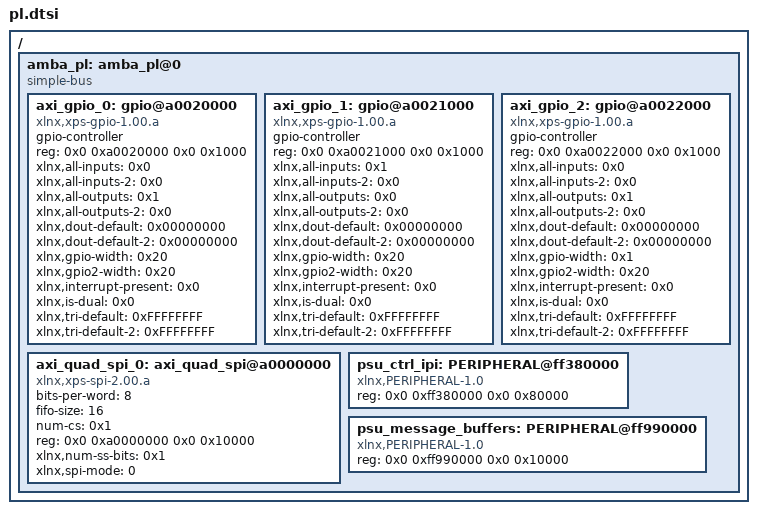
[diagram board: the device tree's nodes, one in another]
/*
 * CAUTION: This file is automatically generated by Xilinx.
 * Version:  
 * Today is: Mon Mar 15 13:33:53 2021
*/


/ {
	amba_pl: amba_pl@0 {
		#address-cells = <2>;
		#size-cells = <2>;
		compatible = "simple-bus";
		ranges ;
		axi_gpio_0: gpio@a0020000 {
			#gpio-cells = <2>;
			compatible = "xlnx,xps-gpio-1.00.a";
			gpio-controller ;
			reg = <0x0 0xa0020000 0x0 0x1000>;
			xlnx,all-inputs = <0x0>;
			xlnx,all-inputs-2 = <0x0>;
			xlnx,all-outputs = <0x1>;
			xlnx,all-outputs-2 = <0x0>;
			xlnx,dout-default = <0x00000000>;
			xlnx,dout-default-2 = <0x00000000>;
			xlnx,gpio-width = <0x20>;
			xlnx,gpio2-width = <0x20>;
			xlnx,interrupt-present = <0x0>;
			xlnx,is-dual = <0x0>;
			xlnx,tri-default = <0xFFFFFFFF>;
			xlnx,tri-default-2 = <0xFFFFFFFF>;
		};
		axi_gpio_1: gpio@a0021000 {
			#gpio-cells = <2>;
			compatible = "xlnx,xps-gpio-1.00.a";
			gpio-controller ;
			reg = <0x0 0xa0021000 0x0 0x1000>;
			xlnx,all-inputs = <0x1>;
			xlnx,all-inputs-2 = <0x0>;
			xlnx,all-outputs = <0x0>;
			xlnx,all-outputs-2 = <0x0>;
			xlnx,dout-default = <0x00000000>;
			xlnx,dout-default-2 = <0x00000000>;
			xlnx,gpio-width = <0x20>;
			xlnx,gpio2-width = <0x20>;
			xlnx,interrupt-present = <0x0>;
			xlnx,is-dual = <0x0>;
			xlnx,tri-default = <0xFFFFFFFF>;
			xlnx,tri-default-2 = <0xFFFFFFFF>;
		};
		axi_gpio_2: gpio@a0022000 {
			#gpio-cells = <2>;
			compatible = "xlnx,xps-gpio-1.00.a";
			gpio-controller ;
			reg = <0x0 0xa0022000 0x0 0x1000>;
			xlnx,all-inputs = <0x0>;
			xlnx,all-inputs-2 = <0x0>;
			xlnx,all-outputs = <0x1>;
			xlnx,all-outputs-2 = <0x0>;
			xlnx,dout-default = <0x00000000>;
			xlnx,dout-default-2 = <0x00000000>;
			xlnx,gpio-width = <0x1>;
			xlnx,gpio2-width = <0x20>;
			xlnx,interrupt-present = <0x0>;
			xlnx,is-dual = <0x0>;
			xlnx,tri-default = <0xFFFFFFFF>;
			xlnx,tri-default-2 = <0xFFFFFFFF>;
		};
		axi_quad_spi_0: axi_quad_spi@a0000000 {
			bits-per-word = <8>;
			compatible = "xlnx,xps-spi-2.00.a";
			fifo-size = <16>;
			num-cs = <0x1>;
			reg = <0x0 0xa0000000 0x0 0x10000>;
			xlnx,num-ss-bits = <0x1>;
			xlnx,spi-mode = <0>;
		};
		psu_ctrl_ipi: PERIPHERAL@ff380000 {
			compatible = "xlnx,PERIPHERAL-1.0";
			reg = <0x0 0xff380000 0x0 0x80000>;
		};
		psu_message_buffers: PERIPHERAL@ff990000 {
			compatible = "xlnx,PERIPHERAL-1.0";
			reg = <0x0 0xff990000 0x0 0x10000>;
		};
	};
};
